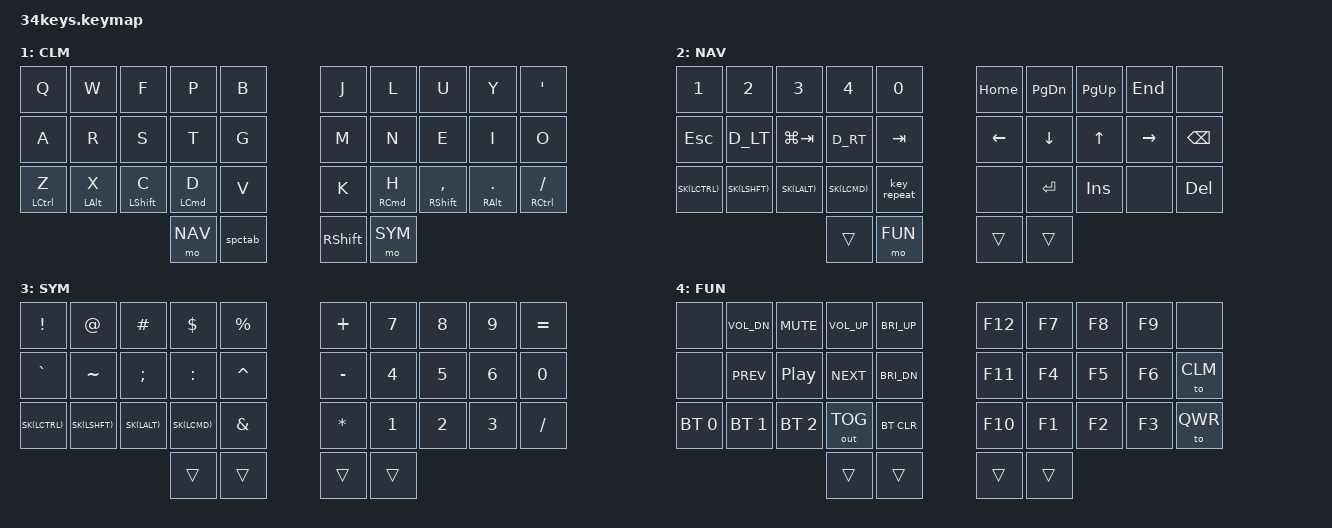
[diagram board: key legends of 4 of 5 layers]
#include <behaviors.dtsi>
#include <dt-bindings/zmk/keys.h>
#include <dt-bindings/zmk/bt.h>
#include <dt-bindings/zmk/outputs.h>

#define xxx &none
#define ___ &trans

// layer definitions
#define QWR 0
#define CLM 1
#define NAV 2
#define SYM 3
#define FUN 4

#define STICKY_KEY_TIMEOUT 60000

// see &nk behavior below
#define SK(KEY) &nk KEY KEY

// custom keycodes
#define MEH        LS(LA(LCTRL))
#define D_LT       LC(LA(P))
#define D_RT       LC(LA(N))
#define TAB_RT     LC(TAB)
#define TAB_LT     LC(LS(TAB))
#define BSPCWRD    LA(LC(BSPC))
#define UNDO_MAC   LG(Z)
#define REDO_MAC   LG(LS(Z))

// shortcut for mods
#define AML(k1,k2,k3,k4) &am LCTRL k1  &am LSHIFT k2  &am LALT k3    &am LCMD k4
#define AMR(k1,k2,k3,k4) &am LCMD k1   &am LALT k2    &am LSHIFT k3  &am LCTRL k4

&sk {
  release-after-ms = <STICKY_KEY_TIMEOUT>;
};

&caps_word {
  continue-list = <UNDERSCORE MINUS BACKSPACE>;
};

&kscan0 {
  debounce-period = <14>;
};

/ {
  combos {
    #include "combos.dtsi"
  };

  behaviors {
    spctab: space_tab {
      compatible = "zmk,behavior-mod-morph";
      label = "SPC_TAB";
      #binding-cells = <0>;
      bindings = <&kp SPACE>, <&kp TAB>;
      mods = <(MOD_LALT)>;
    };

    skq: sticky_key_quick_release {
      compatible = "zmk,behavior-sticky-key";
      label = "STICKY_KEY_QUICK_RELEASE";
      #binding-cells = <1>;
      bindings = <&kp>;
      quick-release;
      release-after-ms = <STICKY_KEY_TIMEOUT>;
    };

    am: alpha_modes {
      compatible = "zmk,behavior-hold-tap";
      label = "ALPHA_MODS";
      #binding-cells = <2>;
      tapping-term-ms = <180>;
      quick-tap-ms = <240>;
      flavor = "tap-preferred";
      bindings = <&kp>, <&kp>;
    };

    // normal key on hold, sticky on tap
    // this is useful for combining mods with mouse actions
    nk: not_so_sticky_key {
      compatible = "zmk,behavior-hold-tap";
      label = "NOT_SO_STICKY_KEY";
      #binding-cells = <2>;
      tapping_term_ms = <200>;
      flavor = "tap-preferred";
      bindings = <&kp>, <&sk>;
    };
  };

keymap {
    compatible = "zmk,keymap";
// ╭─────────────┬─────────────┬─────────────┬─────────────┬─────────────╮   ╭─────────────┬─────────────┬─────────────┬─────────────┬─────────────╮
// ├─────────────┼─────────────┼─────────────┼─────────────┼─────────────┤   ├─────────────┼─────────────┼─────────────┼─────────────┼─────────────┤
// ├─────────────┼─────────────┼─────────────┼─────────────┼─────────────┤   ├─────────────┼─────────────┼─────────────┼─────────────┼─────────────┤
// ╰─────────────┴─────────────┴─────────────┼─────────────┼─────────────┤   ├─────────────┼─────────────┼─────────────┴─────────────┴─────────────╯
//                                           ╰─────────────┴─────────────╯   ╰─────────────┴─────────────╯

    qwerty_layer {
      label = "QWR";
      bindings = <
// ╭─────────────┬─────────────┬─────────────┬─────────────┬─────────────╮   ╭─────────────┬─────────────┬─────────────┬─────────────┬─────────────╮
    &kp Q         &kp W         &kp E         &kp R         &kp T             &kp Y         &kp U         &kp I         &kp O         &kp P
    &kp A         &kp S         &kp D         &kp F         &kp G             &kp H         &kp J         &kp K         &kp L         &kp SQT
    AML(Z        ,    X        ,    C        ,    V)        &kp B             &kp N         AMR(M        ,    COMMA    ,    DOT      ,    FSLH)
// ╰─────────────┴─────────────┴─────────────┼─────────────┼─────────────┤   ├─────────────┼─────────────┼─────────────┴─────────────┴─────────────╯
                                              &mo NAV       &spctab           &kp RSHFT     &mo SYM
//                                           ╰─────────────┴─────────────╯   ╰─────────────┴─────────────╯
      >;
    };

    colemak_layer {
      label = "CLM";
      bindings = <
// ╭─────────────┬─────────────┬─────────────┬─────────────┬─────────────╮   ╭─────────────┬─────────────┬─────────────┬─────────────┬─────────────╮
    &kp Q         &kp W         &kp F         &kp P         &kp B             &kp J         &kp L         &kp U         &kp Y         &kp SQT
    &kp A         &kp R         &kp S         &kp T         &kp G             &kp M         &kp N         &kp E         &kp I         &kp O
    &am LCTRL Z    &am LALT X    &am LSHFT C   &am LCMD D    &kp V             &kp K         &am RCMD H    &am RSHFT COMMA  &am RALT DOT  &am RCTRL FSLH
// ╰─────────────┴─────────────┴─────────────┼─────────────┼─────────────┤   ├─────────────┼─────────────┼─────────────┴─────────────┴─────────────╯
                                              &mo NAV       &spctab           &kp RSHFT     &mo SYM
//                                           ╰─────────────┴─────────────╯   ╰─────────────┴─────────────╯
      >;
    };

    nav_layer {
      label = "NAV";
      bindings = <
// ╭─────────────┬─────────────┬─────────────┬─────────────┬─────────────╮   ╭─────────────┬─────────────┬─────────────┬─────────────┬─────────────╮
    &kp N1        &kp N2        &kp N3        &kp N4        &kp N0            &kp HOME      &kp PG_DN     &kp PG_UP     &kp END       xxx
    &kp ESC       &kp D_LT      &kp LG(TAB)   &kp D_RT      &kp TAB           &kp LEFT      &kp DOWN      &kp UP        &kp RIGHT     &kp BSPC
    SK(LCTRL)      SK(LSHFT)     SK(LALT)      SK(LCMD)      &key_repeat       xxx           &kp RET       &kp INS       xxx           &kp DEL
// ╰─────────────┴─────────────┴─────────────┼─────────────┼─────────────┤   ├─────────────┼─────────────┼─────────────┴─────────────┴─────────────╯
                                              ___           &mo FUN           ___           ___
//                                           ╰─────────────┴─────────────╯   ╰─────────────┴─────────────╯
      >;
    };

    symbol_layer {
      label = "SYM";
      bindings = <
// ╭─────────────┬─────────────┬─────────────┬─────────────┬─────────────╮   ╭─────────────┬─────────────┬─────────────┬─────────────┬─────────────╮
    &kp EXCL      &kp AT        &kp HASH      &kp DLLR      &kp PRCNT         &kp PLUS      &kp N7        &kp N8        &kp N9        &kp EQUAL
    &kp GRAVE     &kp TILDE     &kp SEMI      &kp COLON     &kp CARET         &kp MINUS     &kp N4        &kp N5        &kp N6        &kp N0
    SK(LCTRL)      SK(LSHFT)     SK(LALT)      SK(LCMD)      &kp AMPS          &kp STAR      &kp N1        &kp N2        &kp N3        &kp FSLH
// ╰─────────────┴─────────────┴─────────────┼─────────────┼─────────────┤   ├─────────────┼─────────────┼─────────────┴─────────────┴─────────────╯
                                              ___           ___               ___           ___
//                                           ╰─────────────┴─────────────╯   ╰─────────────┴─────────────╯
      >;
    };


    function_layer {
      label = "FUN";
      bindings = <
// ╭─────────────┬─────────────┬─────────────┬─────────────┬─────────────╮   ╭─────────────┬─────────────┬─────────────┬─────────────┬─────────────╮
    xxx           &kp C_VOL_DN  &kp C_MUTE    &kp C_VOL_UP  &kp C_BRI_UP      &kp F12       &kp F7        &kp F8        &kp F9        xxx
    xxx           &kp C_PREV    &kp C_PP      &kp C_NEXT    &kp C_BRI_DN      &kp F11       &kp F4        &kp F5        &kp F6        &to CLM
    &bt BT_SEL 0  &bt BT_SEL 1  &bt BT_SEL 2  &out OUT_TOG  &bt BT_CLR        &kp F10       &kp F1        &kp F2        &kp F3        &to QWR
// ╰─────────────┴─────────────┴─────────────┼─────────────┼─────────────┤   ├─────────────┼─────────────┼─────────────┴─────────────┴─────────────╯
                                              ___           ___               ___           ___
//                                           ╰─────────────┴─────────────╯   ╰─────────────┴─────────────╯
      >;
    };

  };
};

// vim:ft=c
